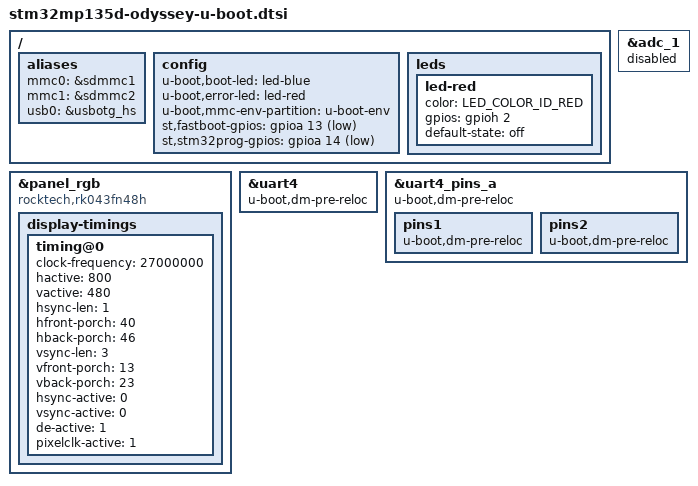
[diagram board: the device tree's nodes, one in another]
// SPDX-License-Identifier: GPL-2.0-or-later OR BSD-3-Clause
/*
 * Copyright (C) STMicroelectronics 2021 - All Rights Reserved
 */

#include "stm32mp13-u-boot.dtsi"

/ {
	aliases {
		mmc0 = &sdmmc1;
		mmc1 = &sdmmc2;
		usb0 = &usbotg_hs;
	};

	config {
		u-boot,boot-led = "led-blue";
		u-boot,error-led = "led-red";
		u-boot,mmc-env-partition = "u-boot-env";
		/*st,adc_usb_pd = <&adc1 6>, <&adc1 12>;*/
		st,fastboot-gpios = <&gpioa 13 (GPIO_ACTIVE_LOW | GPIO_PULL_UP)>;
		st,stm32prog-gpios = <&gpioa 14 (GPIO_ACTIVE_LOW | GPIO_PULL_UP)>;
	};

	leds {
		led-red {
			color = <LED_COLOR_ID_RED>;
			gpios = <&gpioh 2 GPIO_ACTIVE_HIGH>;
			default-state = "off";
		};
	};
};

&adc_1 {
	status = "disabled";
};

&panel_rgb {
	compatible = "rocktech,rk043fn48h","simple-panel";

	display-timings {
		timing@0 {
			clock-frequency = <27000000>;
			hactive = <800>;
			vactive = <480>;

			hsync-len = <1>;
			hfront-porch = <40>;
			hback-porch = <46>;

			vsync-len = <3>;
			vfront-porch = <13>;
			vback-porch = <23>;

			hsync-active = <0>;
			vsync-active = <0>;
			de-active = <1>;
			pixelclk-active = <1>;
		};
	};
};

&uart4 {
	u-boot,dm-pre-reloc;
};

&uart4_pins_a {
	u-boot,dm-pre-reloc;
	pins1 {
		u-boot,dm-pre-reloc;
	};
	pins2 {
		u-boot,dm-pre-reloc;
	};
};
